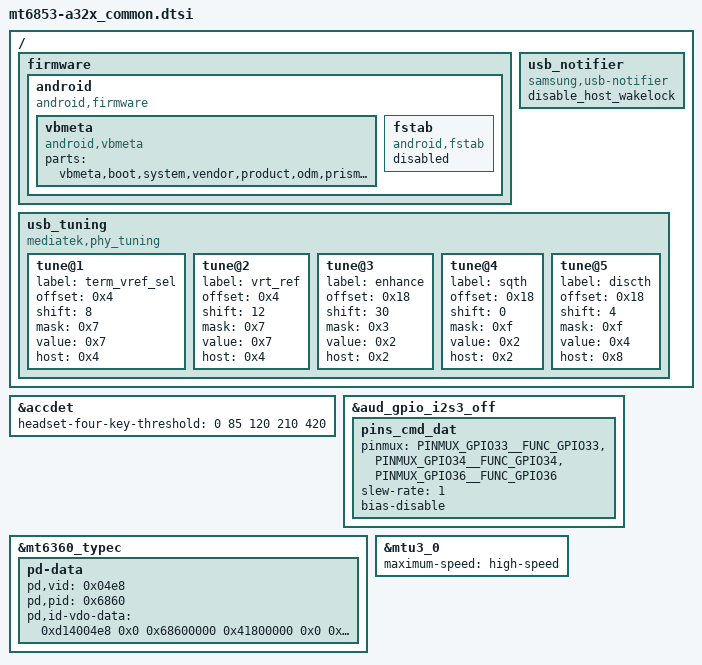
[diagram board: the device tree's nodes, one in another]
/* Generated by Samsung for MTK vendor board 
 * If these files should be changed, then please make a sync with MTK
*/

#include "mt6853_input_a32x_common.dtsi"

/* Add Samsung configuration over here */
/ {
	fragment@model {
		target-path = "/";
		__overlay__ {
			firmware {
				android {
					compatible = "android,firmware";
					vbmeta {
						compatible = "android,vbmeta";
						parts = "vbmeta,boot,system,vendor,product,odm,prism,optics,vbmeta_system,recovery,lk,tee1";
					};
					fstab {
						compatible = "android,fstab";
						status = "disabled";
					};
				};
			};
			usb_notifier {
				compatible = "samsung,usb-notifier";
				disable_host_wakelock;
			};

			usb_tuning:usb_tuning {
				compatible = "mediatek,phy_tuning";

				tune@1 {
					label = "term_vref_sel";
					offset = <0x4>;
					shift = <8>;
					mask = <0x7>;
					value = <0x7>;
					host = <0x4>;
				};

				tune@2 {
					label = "vrt_ref";
					offset = <0x4>;
					shift = <12>;
					mask = <0x7>;
					value = <0x7>;
					host = <0x4>;
				};

				tune@3 {
					label = "enhance";
					offset = <0x18>;
					shift = <30>;
					mask = <0x3>;
					value = <0x2>;
					host = <0x2>;
				};

				tune@4 {
					label = "sqth";
					offset = <0x18>;
					shift = <0>;
					mask = <0xf>;
					value = <0x2>;
					host = <0x2>;
				};

				tune@5 {
					label = "discth";
					offset = <0x18>;
					shift = <4>;
					mask = <0xf>;
					value = <0x4>;
					host = <0x8>;
				};
			};
		};
	};
};

/* accdet start */
&accdet {
	headset-four-key-threshold = <0 85 120 210 420>;
};
/* accdet end */

/* I2S gpio configuration */
&aud_gpio_i2s3_off {
	pins_cmd_dat {
		pinmux = <PINMUX_GPIO33__FUNC_GPIO33>,
			 <PINMUX_GPIO34__FUNC_GPIO34>,
			 <PINMUX_GPIO36__FUNC_GPIO36>;
		slew-rate = <1>;
		bias-disable;
	};
};

&mt6360_typec {
	pd-data {
		pd,vid = <0x04e8>;
		pd,pid = <0x6860>;
		pd,id-vdo-data = <0xd14004e8 0x0 0x68600000
				 0x41800000 0x0 0x21800000>;
	};
};

&mtu3_0 {
	maximum-speed = "high-speed";
};
